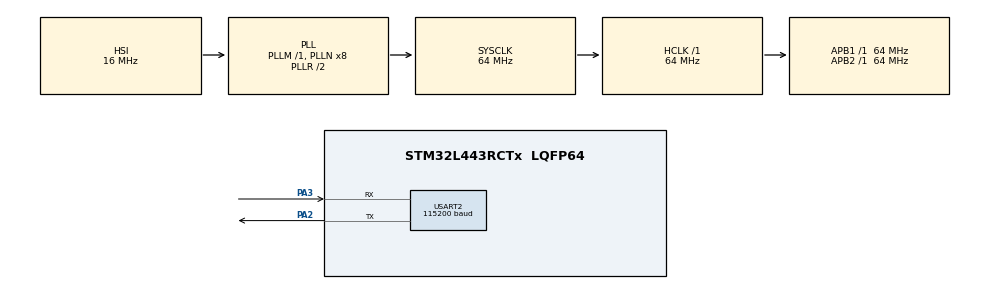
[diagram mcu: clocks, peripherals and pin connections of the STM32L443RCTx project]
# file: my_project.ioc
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Mcu.Family=STM32L4
RCC.MSI_VALUE=4000000
RCC.PLLSourceVirtual=RCC_PLLSOURCE_HSI
PA14\ (JTCK-SWCLK).Mode=Serial_Wire
FREERTOS.Queues01=myQueue01,5,uint32_t,0,Dynamic,NULL,NULL
RCC.CortexFreq_Value=64000000
FREERTOS.Tasks01=myTask01,0,128,StartTask01,Default,NULL,Dynamic,NULL,NULL;myTask02,0,128,StartTask02,Default,NULL,Dynamic,NULL,NULL;myTask03,0,128,StartTask03,Default,NULL,Dynamic,NULL,NULL;myTask04,0,128,StartTask04,Default,NULL,Dynamic,NULL,NULL;myTask05,0,128,StartTask05,Default,NULL,Dynamic,NULL,NULL;myTask06,1,128,StartTask06,Default,NULL,Dynamic,NULL,NULL
FREERTOS.BinarySemaphores01=myBinarySem01,Dynamic,NULL;myBinarySem02,Dynamic,NULL
Dma.USART2_TX.0.MemInc=DMA_MINC_ENABLE
Dma.USART2_TX.0.PeriphDataAlignment=DMA_PDATAALIGN_BYTE
VP_IWDG_VS_IWDG.Mode=IWDG_Activate
FREERTOS.INCLUDE_vTaskDelayUntil=1
FREERTOS.configTICK_RATE_HZ=1000
FREERTOS.CountingSemaphores01=myCountingSem01,3,Dynamic,NULL
NVIC.USART2_IRQn=true\:5\:0\:false\:false\:true\:true\:true\:true
USART2.BaudRate=115200
RCC.SYSCLKSource=RCC_SYSCLKSOURCE_PLLCLK
ProjectManager.StackSize=0x400
FREERTOS.INCLUDE_uxTaskGetStackHighWaterMark=0
PA14\ (JTCK-SWCLK).Signal=SYS_JTCK-SWCLK
FREERTOS.configUSE_IDLE_HOOK=1
PA3.Mode=Asynchronous
FREERTOS.configENABLE_FPU=0
Dma.USART2_TX.0.Priority=DMA_PRIORITY_LOW
ProjectManager.TargetToolchain=STM32CubeIDE
RCC.HCLKFreq_Value=64000000
RCC.APB2TimFreq_Value=64000000
RCC.USBFreq_Value=64000000
RCC.LSE_VALUE=32768
RCC.AHBFreq_Value=64000000
RCC.HSE_VALUE=8000000
board=custom
USART2.VirtualMode-Asynchronous=VM_ASYNC
RCC.VCOOutputFreq_Value=128000000
RCC.APB2Freq_Value=64000000
VP_SYS_VS_tim1.Mode=TIM1
RCC.ADCFreq_Value=64000000
Dma.USART2_TX.0.MemDataAlignment=DMA_MDATAALIGN_BYTE
VP_FREERTOS_VS_CMSIS_V1.Mode=CMSIS_V1
Dma.USART2_TX.0.Direction=DMA_MEMORY_TO_PERIPH
Dma.USART2_TX.0.Instance=DMA1_Channel7
Mcu.Name=STM32L443RCTx
FREERTOS.configTOTAL_HEAP_SIZE=6000
PA2.Signal=USART2_TX
FREERTOS.INCLUDE_uxTaskGetStackHighWaterMark2=1
PA13\ (JTMS-SWDIO).Mode=Serial_Wire
RCC.SYSCLKFreq_VALUE=64000000
Mcu.Package=LQFP64
FREERTOS.configUSE_COUNTING_SEMAPHORES=1
NVIC.TimeBase=TIM1_UP_TIM16_IRQn
Dma.USART2_TX.0.PeriphInc=DMA_PINC_DISABLE
NVIC.TimeBaseIP=TIM1
ProjectManager.HeapSize=0x200
RCC.HSI_VALUE=16000000
FREERTOS.Mutexes01=myMutex01,Dynamic,NULL
NVIC.TIM1_UP_TIM16_IRQn=true\:0\:0\:false\:false\:true\:false\:false\:true
Dma.USART2_TX.0.Mode=DMA_NORMAL
NVIC.PriorityGroup=NVIC_PRIORITYGROUP_4
IWDG.Prescaler=IWDG_PRESCALER_256
RCC.APB1TimFreq_Value=64000000
PA2.Mode=Asynchronous
NVIC.DMA1_Channel7_IRQn=true\:5\:0\:false\:false\:true\:true\:false\:true
PA13\ (JTMS-SWDIO).Signal=SYS_JTMS-SWDIO
Dma.Request0=USART2_TX
RCC.APB1Freq_Value=64000000
IWDG.Window=4095
RCC.HSI48_VALUE=48000000
PA3.Signal=USART2_RX

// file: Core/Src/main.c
/* USER CODE BEGIN Header */
/**
  ******************************************************************************
  * @file           : main.c
  * @brief          : Main program body
  ******************************************************************************
  * @attention
  *
  * <h2><center>&copy; Copyright (c) 2021 STMicroelectronics.
  * All rights reserved.</center></h2>
  *
  * This software component is licensed by ST under BSD 3-Clause license,
  * the "License"; You may not use this file except in compliance with the
  * License. You may obtain a copy of the License at:
  *                        opensource.org/licenses/BSD-3-Clause
  *
  ******************************************************************************
  */
/* USER CODE END Header */
#include "main.h"
#include "cmsis_os.h"
#include "dma.h"
#include "iwdg.h"
#include "usart.h"
#include "gpio.h"

/* USER CODE BEGIN Includes */
//#include "stdlib.h"
#include "usart.h"
#include "stdio.h"
#include "string.h"
/* USER CODE END Includes */

/* USER CODE BEGIN PV */

size_t 	process_stack_point_p32_1;
size_t 	process_stack_point_p32_2;

uint32_t 	process_stack_point__use_func_p32_1;
uint32_t 	process_stack_point__use_func_p32_2;

uint32_t 	*main_stack_point_p32_1;
uint32_t 	*main_stack_point_p32_2;

uint32_t 	main_stack_point_use_func_p32_1;
uint32_t 	main_stack_point_use_func_p32_2;

extern DMA_HandleTypeDef hdma_usart2_tx;
extern volatile uint8_t flag_dma_uart2;

char str[100] = {0};
sData sLog;
size_t heap_size_free;

/* USER CODE END PV */

void SystemClock_Config(void);
void MX_FREERTOS_Init(void);
/* USER CODE BEGIN PFP */
//uint8_t my_function1(void)
//{
//
//	process_stack_point_p32_1 = xPortGetFreeHeapSize();
////	main_stack_point_use_func_p32_1 = __get_MSP();
//
//	//process_stack_point__use_func_p32_1 = __get_PSP();
//
//	uint8_t 	var_test_u8[200]= {0};
////	uint8_t var1_u8[50] = {0};
////	uint8_t var2_u8[50] = {0};
////	uint8_t var3_u8[50] = {0};
////	uint8_t i = 0;
////	uint8_t *heap_test = (uint8_t *) malloc(sizeof(uint8_t*));
////	uint8_t *heap_thread = (uint8_t *) pvPortMalloc(sizeof(uint8_t));
//
//	process_stack_point_p32_2 = xPortGetFreeHeapSize();
//	main_stack_point_use_func_p32_2 = __get_MSP();
////	process_stack_point__use_func_p32_1 = heap_thread;
////	process_stack_point__use_func_p32_2 = __get_PSP();
//	process_stack_point__use_func_p32_1 = __get_PSP();
//	main_stack_point_p32_1 = &var_test_u8[0];
////	main_stack_point_p32_2 = &var1_u8[0];
//
////	var1_u8[0] = var_test_u8;
////	var2_u8[0] = var_test_u8;
////	var3_u8[0] = var_test_u8;
////	var_test_u8 = var1_u8[0];
////	var_test_u8 = var2_u8[0];
////	var_test_u8 = var3_u8[0];
//
////	HAL_Delay(500);
//
//	//for (i = 0; i < 100; i++) {
////		var3_u8[i] = var1_u8[i] + var2_u8[i] + 1;
//	//}
////		*heap_test  = i;
////		*heap_thread = i;
//
////	free(heap_test);
////	vPortFree(heap_thread);
//
//}
//void my_function2(void)
//{
//	uint8_t 	var_test_u8 = 10;
//
//	uint8_t var1_u8[50] = {0};
//	uint8_t var2_u8[50] = {0};
//	uint8_t var3_u8[50] = {0};
//	uint8_t i = 0;
//	uint8_t *heap_test = (uint8_t *) malloc(sizeof(uint8_t*));
//	uint8_t *heap_thread = (uint8_t *) pvPortMalloc(sizeof(uint8_t));
//	//uint8_t *heap_task = (uint8_t *) pvPortMalloc(sizeof(uint8_t));
//
//	var1_u8[0] = var_test_u8;
//	var2_u8[0] = var_test_u8;
//	var3_u8[0] = var_test_u8;
////	var_test_u8 = var1_u8[0];
////	var_test_u8 = var2_u8[0];
////	var_test_u8 = var3_u8[0];
//
////	HAL_Delay(500);
//
//	//for (i = 0; i < 100; i++) {
//		var3_u8[i] = var1_u8[i] + var2_u8[i] + 1;
//	//}
//	*heap_test  = i;
//	*heap_thread = i;
//	//*heap_task = i;
//
//	//process_stack_point_p32 = xPortGetFreeHeapSize();
//	my_function1();
//
//	free(heap_test);
//	vPortFree(heap_thread);
//	//vPortFree(heap_task);
//
//}
//void my_function3(void)
//{
//	uint8_t 	var_test_u8 = 10;
//
//	uint8_t var1_u8[50] = {0};
//	uint8_t var2_u8[50] = {0};
//	uint8_t var3_u8[50] = {0};
//	uint8_t i = 0;
//
//	var1_u8[0] = var_test_u8;
//	var2_u8[0] = var_test_u8;
//	var3_u8[0] = var_test_u8;
//	var_test_u8 = var1_u8[0];
//	var_test_u8 = var2_u8[0];
//	var_test_u8 = var3_u8[0];
//
////	HAL_Delay(500);
//
//	//for (i = 0; i < 100; i++) {
//		var3_u8[i] = var1_u8[i] + var2_u8[i] + 1;
//	//}
//
//	my_function2();
//	//my_function3();
//}
//
//void my_submain_function(void)
//{
//	uint8_t 	var_test_u8 = 10;
//	uint32_t 	var_global_u32 = 0;
//	uint8_t 	array_u8[100] = {0};
//
//	uint32_t var_test1_su8 = 0;
//	uint32_t var_test1_su32 = 0;
//	uint32_t var_test2_su32 = 0;
//	uint32_t var_test3_su32 = 0;
//	//uint32_t var_test4_su32 = 0;
//
//	  var_test_u8++;
//	  var_global_u32++;
//	  array_u8[0]++;
//	  var_test1_su8++;
//	  var_test1_su32++;
//	  var_test2_su32++;
//	  var_test3_su32++;
//	//	  var_test4_su32++;
//	  if (var_global_u32 == var_test_u8)
//	  {
//		  var_test_u8++;
//		  var_global_u32++;
//	  }
//	  var_test_u8 = var_test1_su8;
//	  var_test_u8 = var_test1_su32;
//	  var_test_u8 = var_test2_su32;
//	  var_test_u8 = var_test3_su32;
//	//	  var_test_u8 = var_test4_su32;
//	  var_test_u8 = array_u8[0];
//}
//
//void led_control(void)
//{
////	HAL_Delay(200);
////	HAL_GPIO_TogglePin(LED_USER_GPIO_Port, LED_USER_Pin);
////	HAL_Delay(200);
//}
//
////void (* pCallback)( DMA_HandleTypeDef * _hdma)
//void my_callback_dma(DMA_HandleTypeDef * _hdma)
//{
//	//flag_dma_uart2 = 1;
//}

/* USER CODE END PFP */

/* USER CODE BEGIN 0 */
int _write(int file, char *ptr, int len)
{
  /* Implement your write code here, this is used by puts and printf for example */
//  heap_size_free = xPortGetMinimumEverFreeHeapSize();
  HAL_UART_Transmit(&huart2, (uint8_t *)ptr, len, 2000);

//  int i=0;
//  for(i=0 ; i<len ; i++)
//    ITM_SendChar((*ptr++));
  return len;
}

int _read(int fd, char* ptr, int len)
{
	HAL_StatusTypeDef hstatus;

	if (fd == 0) {
		hstatus = HAL_UART_Receive(&huart2, (uint8_t *) sLog.data, 1, HAL_MAX_DELAY);
		if (hstatus == HAL_OK) {
			sLog.length++;
			return 1;
		} else {
			return 5;
		}
	}

	return -1;
}
/* USER CODE END 0 */

int main(void)
{

  /* MCU Configuration--------------------------------------------------------*/

  /* Reset of all peripherals, Initializes the Flash interface and the Systick. */
  HAL_Init();

  /* Configure the system clock */
  SystemClock_Config();

  /* Initialize all configured peripherals */
  MX_GPIO_Init();
  MX_DMA_Init();
  MX_USART2_UART_Init();
  MX_IWDG_Init();
  /* USER CODE BEGIN 2 */
  __HAL_IWDG_START(&hiwdg);
  sLog.data = str;
  HAL_UART_Transmit(&huart2, (uint8_t *)"hello world\r\n", 13, 1000);
  HAL_UART_Transmit(&huart2, (uint8_t *)"hello abcde\r\n", 13, 1000); // wrong, never being send
  HAL_Delay(1000);
  printf("123\n");
  /* USER CODE END 2 */

  /* Call init function for freertos objects (in freertos.c) */
  MX_FREERTOS_Init();
  /* Start scheduler */
  osKernelStart();

  /* We should never get here as control is now taken by the scheduler */
  /* Infinite loop */
  /* USER CODE BEGIN WHILE */
  while (1)
  {
	  NVIC_SystemReset();
    /* USER CODE END WHILE */

  }
}

void SystemClock_Config(void)
{
  RCC_OscInitTypeDef RCC_OscInitStruct = {0};
  RCC_ClkInitTypeDef RCC_ClkInitStruct = {0};
  RCC_PeriphCLKInitTypeDef PeriphClkInit = {0};

  /** Initializes the RCC Oscillators according to the specified parameters
  * in the RCC_OscInitTypeDef structure.
  */
  RCC_OscInitStruct.OscillatorType = RCC_OSCILLATORTYPE_HSI|RCC_OSCILLATORTYPE_LSI;
  RCC_OscInitStruct.HSIState = RCC_HSI_ON;
  RCC_OscInitStruct.HSICalibrationValue = RCC_HSICALIBRATION_DEFAULT;
  RCC_OscInitStruct.LSIState = RCC_LSI_ON;
  RCC_OscInitStruct.PLL.PLLState = RCC_PLL_ON;
  RCC_OscInitStruct.PLL.PLLSource = RCC_PLLSOURCE_HSI;
  RCC_OscInitStruct.PLL.PLLM = 1;
  RCC_OscInitStruct.PLL.PLLN = 8;
  RCC_OscInitStruct.PLL.PLLP = RCC_PLLP_DIV7;
  RCC_OscInitStruct.PLL.PLLQ = RCC_PLLQ_DIV2;
  RCC_OscInitStruct.PLL.PLLR = RCC_PLLR_DIV2;
  if (HAL_RCC_OscConfig(&RCC_OscInitStruct) != HAL_OK)
  {
    Error_Handler();
  }
  /** Initializes the CPU, AHB and APB buses clocks
  */
  RCC_ClkInitStruct.ClockType = RCC_CLOCKTYPE_HCLK|RCC_CLOCKTYPE_SYSCLK
                              |RCC_CLOCKTYPE_PCLK1|RCC_CLOCKTYPE_PCLK2;
  RCC_ClkInitStruct.SYSCLKSource = RCC_SYSCLKSOURCE_PLLCLK;
  RCC_ClkInitStruct.AHBCLKDivider = RCC_SYSCLK_DIV1;
  RCC_ClkInitStruct.APB1CLKDivider = RCC_HCLK_DIV1;
  RCC_ClkInitStruct.APB2CLKDivider = RCC_HCLK_DIV1;

  if (HAL_RCC_ClockConfig(&RCC_ClkInitStruct, FLASH_LATENCY_3) != HAL_OK)
  {
    Error_Handler();
  }
  PeriphClkInit.PeriphClockSelection = RCC_PERIPHCLK_USART2;
  PeriphClkInit.Usart2ClockSelection = RCC_USART2CLKSOURCE_PCLK1;
  if (HAL_RCCEx_PeriphCLKConfig(&PeriphClkInit) != HAL_OK)
  {
    Error_Handler();
  }
  /** Configure the main internal regulator output voltage
  */
  if (HAL_PWREx_ControlVoltageScaling(PWR_REGULATOR_VOLTAGE_SCALE1) != HAL_OK)
  {
    Error_Handler();
  }
}

 /**
  * @brief  Period elapsed callback in non blocking mode
  * @note   This function is called  when TIM1 interrupt took place, inside
  * HAL_TIM_IRQHandler(). It makes a direct call to HAL_IncTick() to increment
  * a global variable "uwTick" used as application time base.
  * @param  htim : TIM handle
  * @retval None
  */
void HAL_TIM_PeriodElapsedCallback(TIM_HandleTypeDef *htim)
{
  if (htim->Instance == TIM1) {
    HAL_IncTick();
  }
}

void Error_Handler(void)
{
  __disable_irq();
  while (1)
  {
  }
}

/************************ (C) COPYRIGHT STMicroelectronics *****END OF FILE****/
